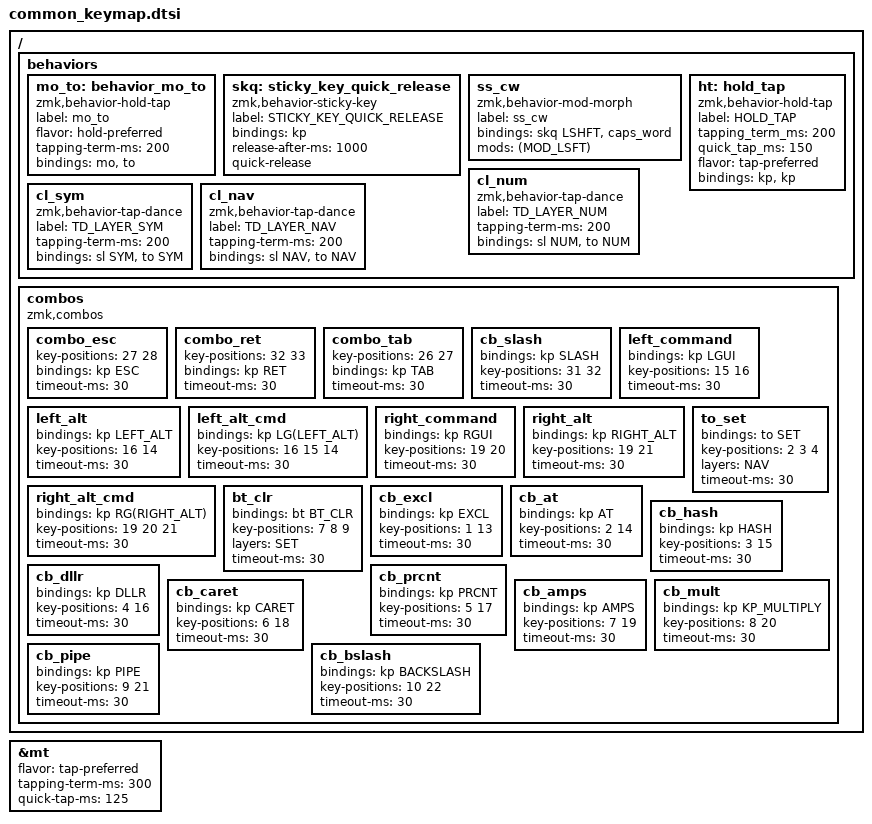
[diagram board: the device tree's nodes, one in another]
#include <behaviors.dtsi>
#include <dt-bindings/zmk/keys.h>
#include <dt-bindings/zmk/bt.h> 
#include <dt-bindings/zmk/rgb.h>
#include <dt-bindings/zmk/ext_power.h>
#include <dt-bindings/zmk/outputs.h>


#define DEF 0  // layer shortcuts, must match order in which they are defined below
#define NUM 1
#define SYM 2
#define NAV 3
#define SET 4
// #define DBLO 5

#define MO_TO(layer) &mo_to layer layer   // Macro to apply momentary-layer-on-hold/to-layer-on-tap to a specific layer

&mt {
  flavor = "tap-preferred";
  tapping-term-ms = <300>; 
  quick-tap-ms = <125>;
  
};

/ {
  behaviors {
    // momentary on hold, toggle on tap
    mo_to: behavior_mo_to {
         compatible = "zmk,behavior-hold-tap";
         label = "mo_to";
         #binding-cells = <2>;
         flavor = "hold-preferred";
         tapping-term-ms = <200>;
         bindings = <&mo>, <&to>;
    };

    // prevent multiple uppercase letters on sticky shift https://github.com/zmkfirmware/zmk/issues/903
    skq: sticky_key_quick_release {
        compatible = "zmk,behavior-sticky-key";
        label = "STICKY_KEY_QUICK_RELEASE";
        #binding-cells = <1>;
        bindings = <&kp>;
        release-after-ms = <1000>;
        quick-release;
    };
    // tap: sticky-shift | lshft + tap: caps-word | hold: shift
    // from https://github.com/urob/zmk-config/blob/main/config/base.keymap 
    ss_cw: ss_cw {
         compatible = "zmk,behavior-mod-morph";
         #binding-cells = <0>;
         label = "ss_cw";
         bindings = <&skq LSHFT>, <&caps_word>;
         mods = <(MOD_LSFT)>;
    };

    ht: hold_tap {
        compatible = "zmk,behavior-hold-tap";
        label = "HOLD_TAP";
        #binding-cells = <2>;
        tapping_term_ms = <200>;
        quick_tap_ms = <150>;
        flavor = "tap-preferred";
        bindings = <&kp>, <&kp>;
    };

    // tap: sticky layer 1 | double tap: toggle layer 1
    cl_num: cl_num {
        compatible = "zmk,behavior-tap-dance";
        label = "TD_LAYER_NUM";
        #binding-cells = <0>;
        tapping-term-ms = <200>;
        bindings = <&sl NUM>, <&to NUM>;
    };

     // tap: sticky layer 2 | double tap: toggle layer 2
     cl_sym: cl_sym {
         compatible = "zmk,behavior-tap-dance";
         label = "TD_LAYER_SYM";
         #binding-cells = <0>;
         tapping-term-ms = <200>;
         bindings = <&sl SYM>, <&to SYM>;
     };

     // tap: sticky layer 3 | double tap: toggle layer 3
     cl_nav: cl_nav {
         compatible = "zmk,behavior-tap-dance";
         label = "TD_LAYER_NAV";
         #binding-cells = <0>;
         tapping-term-ms = <200>;
         bindings = <&sl NAV>, <&to NAV>;
     };
  };

  // Key numbers
  // -----------------------------------------------------------------------------------------
  // | NONE |  1  |  2  |  3  |  4  |  5  |   |  6  |  7   |  8  |  9  |  10  | NONE |
  // | NONE |  13 |  14 |  15 |  16 |  17 |   |  18 |  19  |  20 |  21 |  22  | NONE |
  // | NONE |  25 |  26 |  27 |  28 |  29 |   |  30 |  31  |  32 |  33 |  34  | NONE |
  //                                |  36 |   |  37 |
  //              |  38 |  39 |  40 |  41 |   |  42 |  43 |  44  |  45 |

  // Homerow bindings
  combos {
    compatible = "zmk,combos";

    combo_esc {
      key-positions = <27 28>;
      bindings = <&kp ESC>;
      timeout-ms = <30>;
    };

    combo_ret {
      key-positions = <32 33>;
      bindings = <&kp RET>;
      timeout-ms = <30>;
    };

    combo_tab {
      key-positions = <26 27>;
      bindings = <&kp TAB>;
      timeout-ms = <30>;
    };

    cb_slash {
      bindings = <&kp SLASH>;
      key-positions = <31 32>;
      timeout-ms = <30>;
    };

    left_command {
      bindings = <&kp LGUI>;
      key-positions = <15 16>;
      timeout-ms = <30>;
    };

    left_alt {
      bindings = <&kp LEFT_ALT>;
      key-positions = <16 14>;
      timeout-ms = <30>;
    };

    left_alt_cmd {
      bindings = <&kp LG(LEFT_ALT)>;
      key-positions = <16 15 14>;
      timeout-ms = <30>;
    };

    right_command {
      bindings = <&kp RGUI>;
      key-positions = <19 20>;
      timeout-ms = <30>;
    };

    right_alt {
      bindings = <&kp RIGHT_ALT>;
      key-positions = <19 21>;
      timeout-ms = <30>;
    };

    right_alt_cmd {
      bindings = <&kp RG(RIGHT_ALT)>;
      key-positions = <19 20 21>;
      timeout-ms = <30>;
    };

    // settings related combos
    to_set {
      bindings = <&to SET>;
      key-positions = <2 3 4>;
      layers = <NAV>;
      timeout-ms = <30>;
      };
    bt_clr {
      bindings = <&bt BT_CLR>;
      key-positions = <7 8 9>;
      layers = <SET>;
      timeout-ms = <30>;
      };

    // symbols
    cb_excl {
      bindings = <&kp EXCL>;
      key-positions = <1 13>;
      timeout-ms = <30>;
    };

    cb_at {
      bindings = <&kp AT>;
      key-positions = <2 14>;
      timeout-ms = <30>;
    };

    cb_hash {
      bindings = <&kp HASH>;
      key-positions = <3 15>;
      timeout-ms = <30>;
    };

    cb_dllr {
      bindings = <&kp DLLR>;
      key-positions = <4 16>;
      timeout-ms = <30>;
    };


    cb_prcnt {
      bindings = <&kp PRCNT>;
      key-positions = <5 17>;
      timeout-ms = <30>;
    };


    cb_caret {
      bindings = <&kp CARET>;
      key-positions = <6 18>;
      timeout-ms = <30>;
    };


    cb_amps {
      bindings = <&kp AMPS>;
      key-positions = <7 19>;
      timeout-ms = <30>;
    };


    cb_mult {
      bindings = <&kp KP_MULTIPLY>;
      key-positions = <8 20>;
      timeout-ms = <30>;
    };


    cb_pipe {
      bindings = <&kp PIPE>;
      key-positions = <9 21>;
      timeout-ms = <30>;
    };

    cb_bslash {
      bindings = <&kp BACKSLASH>;
      key-positions = <10 22>;
      timeout-ms = <30>;
    };

  };

};

#define __________DEF_L1__________  &none   &kp Q   &kp W   &kp E   &kp R      &kp T
#define __________DEF_L2__________  &none   &kp A   &kp S   &kp D   &kp F      &kp G
#define __________DEF_L3__________  &none   &kp Z   &kp X   &kp C   &kp V      &kp B
#define _________THUMB_DEF_L_______ &cl_num   &cl_sym  &ss_cw &none

#define __________DEF_R1__________  &kp Y      &kp U      &kp I     &kp O   &kp P    &none
#define __________DEF_R2__________  &kp H      &kp J      &kp K     &kp L   &kp SQT  &none
#define __________DEF_R3__________  &kp N      &kp M      &kp COMMA &kp DOT &kp BSPC &none
#define _________THUMB_DEF_R_______ &none &skq LCTRL  &mt LGUI SPACE    &cl_nav


#define __________NUM_L1__________  &none  &kp C_VOLUME_DOWN   &kp C_VOLUME_UP  &kp LG(LSHFT) &kp LGUI       &kp KP_MULTIPLY
#define __________NUM_L2__________  &none  &none               &kp EQUAL        &kp COLON     &none          &kp KP_DIVIDE  
#define __________NUM_L3__________  &none  &kp TAB             &kp C_PLAY_PAUSE &kp C_NEXT    &kp LBKT       &kp KP_EQUAL   
#define _________THUMB_NUM_L_______ &cl_num   &cl_sym  &ss_cw &none

#define __________NUM_R1__________  &kp PLUS         &ht F7 NUMBER_7  &ht F8 NUMBER_8  &ht F9 NUMBER_9    &kp LC(B) &none
#define __________NUM_R2__________  &kp MINUS        &ht F4 NUMBER_4  &ht F5 NUMBER_5  &ht F6 NUMBER_6    &kp ENTER &none
#define __________NUM_R3__________  &kp PERIOD       &ht F1 NUMBER_1  &ht F2 NUMBER_2  &ht F3 NUMBER_3    &trans    &none
#define _________THUMB_NUM_R_______ &none &mt LCTRL NUMBER_0  &to DEF    &cl_nav

#define __________SYM_L1__________  &none  &kp TILDE  &kp COLON         &none      &kp LEFT_PARENTHESIS  &none 
#define __________SYM_L2__________  &none  &kp GRAVE  &kp DOUBLE_QUOTES &kp EQUAL  &kp LEFT_BRACE        &kp LT
#define __________SYM_L3__________  &none  &kp TAB    &none             &none      &kp LEFT_BRACKET      &none 
#define _________THUMB_SYM_L_______ &cl_num   &cl_sym  &ss_cw &none

#define __________SYM_R1__________  &none  &kp RIGHT_PARENTHESIS  &kp PLUS  &kp QMARK  &kp PIPE  &none
#define __________SYM_R2__________  &kp GT &kp RIGHT_BRACE        &kp MINUS &kp UNDER  &kp SEMI  &none
#define __________SYM_R3__________  &none  &kp RIGHT_BRACKET      &trans    &trans     &kp BSPC  &none
#define _________THUMB_SYM_R_______ &none &sk LCTRL  &to DEF    &cl_nav

#define __________NAV_L1__________  &none   &none    &none    &kp LA(RIGHT_ARROW) &kp LG(LS(Z))  &none             
#define __________NAV_L2__________  &none   &none    &none    &kp LG(X)           &none          &none             
#define __________NAV_L3__________  &none   &kp TAB  &kp DEL  &none               &none          &kp LA(LEFT_ARROW)
#define _________THUMB_NAV_L_______ &cl_num    &cl_sym  &ss_cw &none

#define __________NAV_R1__________  &kp LG(C)       &kp LG(Z)             &to DEF                &kp DEL          &kp LG(V)  &none
#define __________NAV_R2__________  &kp LEFT_ARROW  &kp DOWN_ARROW        &kp UP_ARROW           &kp RIGHT_ARROW  &none      &none
#define __________NAV_R3__________  &none           &kp LG(LEFT_BRACKET)  &kp LG(RIGHT_BRACKET)  &none            &trans     &none
#define _________THUMB_NAV_R_______ &none &sk LCTRL  &to DEF    &cl_nav

#define __________SET_L1__________  &none   &none  &none  &none  &none  &none
#define __________SET_L2__________  &none   &none  &none  &none  &none  &none
#define __________SET_L3__________  &none   &none  &none  &none  &none  &none
#define _________THUMB_SET_L_______ &cl_num   &cl_sym  &ss_cw &none

#define __________SET_R1__________  &none    &bt BT_SEL 0 &bt BT_PRV &bt BT_NXT &none    &none
#define __________SET_R2__________  &none    &none        &none      &none      &none    &none
#define __________SET_R3__________  &none    &none        &none      &none      &none    &none
#define _________THUMB_SET_R_______ &none &sk LCTRL  &to DEF    &cl_nav
